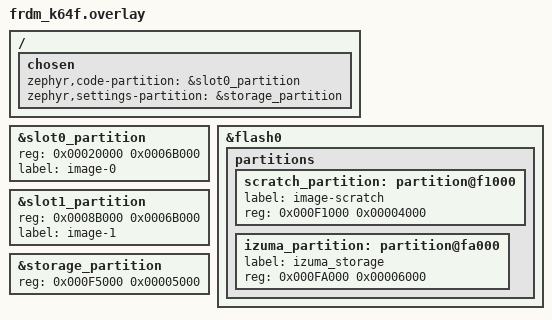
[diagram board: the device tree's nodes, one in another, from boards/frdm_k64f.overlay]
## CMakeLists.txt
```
cmake_minimum_required(VERSION 3.13.1)

# Define configuration files.
set(CONF_FILE "${CMAKE_SOURCE_DIR}/pal-platform/SDK/ZephyrOS/prj.conf")

if (EXISTS "${CMAKE_CURRENT_SOURCE_DIR}/pal-platform/SDK/ZephyrOS/boards/${BOARD}.overlay")
    set(DTC_OVERLAY_FILE "${CMAKE_SOURCE_DIR}/pal-platform/SDK/ZephyrOS/boards/${BOARD}.overlay")
endif()

# Copy Kconfig file to application root for Zephyr to pick it up
configure_file(${CMAKE_SOURCE_DIR}/pal-platform/SDK/ZephyrOS/Kconfig ${CMAKE_SOURCE_DIR} COPYONLY)

find_package(Zephyr REQUIRED HINTS $ENV{ZEPHYR_BASE})
project("Izuma Client")

################################################################################

add_definitions(-DMBED_CONF_APP_DEVELOPER_MODE=$<BOOL:${CONFIG_IZUMA_EXAMPLE_DEVELOPER_MODE}>)

add_definitions(-DMBED_CLOUD_APPLICATION_NONSTANDARD_ENTRYPOINT=1)
add_definitions(-DPAL_USER_DEFINED_CONFIGURATION="pal_config_zephyr.h")
add_definitions(-DPAL_USE_HW_TRNG=1)

# Keep Izuma tracing enabled but limit verbosity to reduce rodata
# and disable certificate enrollment to save flash.
target_compile_definitions(zephyr_interface INTERFACE
    MBED_TRACE_MAX_LEVEL=TRACE_LEVEL_INFO
    MBED_CONF_MBED_CLOUD_CLIENT_DISABLE_CERTIFICATE_ENROLLMENT=1
)

include_directories(${CMAKE_SOURCE_DIR}/pal-platform/SDK/ZephyrOS)
include_directories(${CMAKE_SOURCE_DIR})
include_directories(${CMAKE_SOURCE_DIR}/source)
include_directories(${CMAKE_SOURCE_DIR}/source/include)
include_directories(${CMAKE_SOURCE_DIR}/source/platform/include)

SET(APP_SRCS
    ${CMAKE_SOURCE_DIR}/main.cpp
    ${CMAKE_SOURCE_DIR}/update_ui_example.cpp
    ${CMAKE_SOURCE_DIR}/source/pdmc_example.cpp
    ${CMAKE_SOURCE_DIR}/source/application_init.cpp
    ${CMAKE_SOURCE_DIR}/source/blinky.cpp
    ${CMAKE_SOURCE_DIR}/source/certificate_enrollment_user_cb.cpp
    ${CMAKE_SOURCE_DIR}/source/platform/ZephyrOS/mcc_common_button_and_led.c
    ${CMAKE_SOURCE_DIR}/source/platform/ZephyrOS/mcc_common_setup.c
    ${CMAKE_SOURCE_DIR}/mbed_cloud_dev_credentials.c
    ${CMAKE_SOURCE_DIR}/update_default_resources.c
)

target_sources(app PRIVATE ${CMAKE_SOURCE_DIR}/pal-platform/SDK/ZephyrOS/src/main.cpp ${APP_SRCS})

if(CONFIG_IZUMA_SOURCES)
  target_include_directories(app PRIVATE ${ZEPHYR_BASE}/subsys/storage/flash_map)
  # Copy configuration file to include directory visible for all libraries.
  # Needed for the file to be visible by Zephyr's mbedtls library.
  configure_file("${CMAKE_SOURCE_DIR}/pal-platform/SDK/ZephyrOS/config-tls-generic.h" "${CMAKE_BINARY_DIR}/zephyr/include/generated" COPYONLY)
endif()
```

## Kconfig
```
# Copyright (c) 2021 Pelion
# SPDX-License-Identifier: Apache-2.0

menu "Pelion Device Management Client Example"

comment "    Example application configuration                         "

config PELION_EXAMPLE_DEVELOPER_MODE
    bool "Enable developer mode to skip Factory enrollment"
    default y
    help
      Connect to Pelion DM using developer credentials.

comment "    Library configuration can be found under:                 "
comment "        Modules -> Pelion Device Management Client Library    "

endmenu

source "Kconfig.zephyr"
```

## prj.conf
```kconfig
# Use developer credentials
CONFIG_IZUMA_EXAMPLE_DEVELOPER_MODE=y
CONFIG_IZUMA_UPDATE_DEVELOPER=y

# Enable Pelion Client library
CONFIG_IZUMA_CLIENT=y

# Endpoint type
CONFIG_IZUMA_ENDPOINT_TYPE="default"

# Device registration lifetime
CONFIG_IZUMA_LIFETIME=86400

# Transport mode
CONFIG_IZUMA_TRANSPORT_MODE_TCP=y
#CONFIG_IZUMA_TRANSPORT_MODE_UDP=y
#CONFIG_IZUMA_TRANSPORT_MODE_UDP_QUEUE=y

# CoAP block size
CONFIG_IZUMA_COAP_MAX_BLOCKWISE_PAYLOAD_SIZE=512

# Debug tracing
CONFIG_IZUMA_DEBUG_TRACE=y

# Enable firmware update
CONFIG_IZUMA_UPDATE=y

# Firmware update buffer
CONFIG_IZUMA_UPDATE_BUFFER=1024

# Make new firmware permanent
CONFIG_IZUMA_UPDATE_PERMANENT=y

################################################################################
## Common Zephyr configuration
################################################################################

# Use Mbed TLS from Zephyr with configuration file
CONFIG_MBEDTLS=y
CONFIG_CUSTOM_MBEDTLS_CFG_FILE=y

# Required by Pelion client
CONFIG_NEWLIB_LIBC=y
CONFIG_CPLUSPLUS=y
CONFIG_LIB_CPLUSPLUS=y

# Reduce flash usage: disable float printf and enable LTO
CONFIG_NEWLIB_LIBC_FLOAT_PRINTF=n
# CONFIG_LTO is not available in Zephyr 2.7; leave disabled

# Provide access to flash
CONFIG_FLASH=y
CONFIG_FLASH_MAP=y
CONFIG_FLASH_PAGE_LAYOUT=y
CONFIG_MPU_ALLOW_FLASH_WRITE=y

# Factory provisioning is done in main thread
CONFIG_MAIN_STACK_SIZE=8192

################################################################################
## Network settings
################################################################################

CONFIG_POSIX_API=y

CONFIG_NETWORKING=y
CONFIG_NET_TCP=y
CONFIG_NET_SOCKETS=y
CONFIG_NET_IPV4=y
CONFIG_NET_UDP=y

CONFIG_DNS_RESOLVER=y

CONFIG_NET_DHCPV4=y

CONFIG_NET_MGMT=y
CONFIG_NET_MGMT_EVENT=y
```

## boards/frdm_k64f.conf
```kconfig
# Izuma TDB internal storage configuration
CONFIG_IZUMA_TDB_INTERNAL_STORAGE_SIZE=0x6000
```

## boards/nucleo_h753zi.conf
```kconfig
# --- Console / logging (VCP on USART3) ---
CONFIG_UART_CONSOLE=y
CONFIG_LOG=y
CONFIG_LOG_DEFAULT_LEVEL=3

# --- Stacks/heap (M7 needs more headroom) ---
CONFIG_ISR_STACK_SIZE=4096
CONFIG_HEAP_MEM_POOL_SIZE=32768

# --- Networking driver knobs (if you will use on-board Ethernet) ---
CONFIG_ETH_STM32_HAL=y
CONFIG_NET_L2_ETHERNET=y
CONFIG_NET_IPV4=y
CONFIG_NET_DHCPV4=y

# --- Optional stability knobs (nice during bring-up) ---
CONFIG_ASSERT=y
CONFIG_DEBUG_OPTIMIZATIONS=y

CONFIG_NVS=y

# Izuma TDB internal storage configuration
CONFIG_IZUMA_TDB_INTERNAL_STORAGE_SIZE=0x40000

CONFIG_IZUMA_UPDATE_PAGE_SIZE=32
```

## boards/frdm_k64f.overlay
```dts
/* Align partitions to fit a larger signed image and trailer while staying within 1 MiB
 * Layout summary (addresses in hex):
 *   MCUBoot          : 00000000 - 0001FFFF (128 KiB)
 *   slot0 (image-0)  : 00020000 - 0008AFFF (0x6B000 = 438,272 B)
 *   slot1 (image-1)  : 0008B000 - 000F0FFF (0x6B000)
 *   image-scratch    : 000F1000 - 000F4FFF (0x4000 = 16 KiB)
 *   storage          : 000F5000 - 000FAFFF (0x6000 = 24 KiB)
 *   izuma_storage    : 000FB000 - 000FFFFF (0x5000 = 20 KiB)
 */
/ { chosen { zephyr,code-partition = &slot0_partition; zephyr,settings-partition = &storage_partition; }; };
/delete-node/ &scratch_partition;



/* Common to both MCUboot and APP overlays */
&slot0_partition { reg = <0x00020000 0x0006B000>; label = "image-0"; };
&flash0 {
  partitions {
    scratch_partition: partition@f1000 {   /* 0xF1000–0xF4FFF (16 KiB) */
      label = "image-scratch";
      reg = <0x000F1000 0x00004000>;
    };
  };
};

&slot1_partition { reg = <0x0008B000 0x0006B000>; label = "image-1"; };

&flash0 {
  partitions {
    izuma_partition: partition@fa000 {     /* 0xFA000–0xFFFFF (24 KiB) */
      label = "izuma_storage";
      reg = <0x000FA000 0x00006000>;
    };
    /* We intentionally do not redefine scratch_partition here to avoid duplicating the board-defined label.
     * The board DTS defines scratch_partition with label "image-scratch"; we keep it but shrink it via a
     * delete+recreate below with the same label and a new address range.
     */
  };
};

/* Reposition existing settings/storage partition provided by the board DTS */
&storage_partition {
  reg = <0x000F5000 0x00005000>;
};
```

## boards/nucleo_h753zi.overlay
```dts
/* App executes from slot0; Settings use 'storage' */
&{/chosen} {
	zephyr,code-partition = &slot0_partition;
	zephyr,settings-partition = &storage_partition;
};

/* Storage/NVS: 256 KiB (2 x 128 KiB) */
&storage_partition {
	reg = <0x00020000 0x00040000>;
	label = "storage";
};

/* Slots: 640 KiB each */
&slot0_partition {
	reg = <0x00060000 0x000A0000>;
	label = "image-0";
};

&slot1_partition {
	reg = <0x00100000 0x000A0000>;
	label = "image-1";
};

/* Izuma creds: 256 KiB (2 x 128 KiB) */
&flash0 {
	partitions {
		izuma_partition: partition@100000 {
			label = "izuma_storage";
			reg = <0x001A0000 0x00040000>;
		};
	};
};

/* Scratch: 128 KiB at end of flash */
&scratch_partition {
	reg = <0x001E0000 0x00020000>;
	label = "image-scratch";
};
```

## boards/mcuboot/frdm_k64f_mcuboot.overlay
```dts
&{/chosen} { zephyr,code-partition = &boot_partition; };

/* Common to both MCUboot and APP overlays */
&slot0_partition { reg = <0x00020000 0x00065000>; label = "image-0"; };
&slot1_partition { reg = <0x00085000 0x00065000>; label = "image-1"; };

&flash0 {
  partitions {
    storage_partition: partition@e1000 {  /* 0xE1000–0xE9FFF (36 KiB) */
      label = "storage";
      reg = <0x000E1000 0x00009000>;
    };
    scratch_partition: partition@ea000 {   /* 0xEA000–0xF9FFF (64 KiB) */
      label = "image-scratch";
      reg = <0x000EA000 0x00010000>;
    };
    izuma_partition: partition@fa000 {     /* 0xFA000–0xFFFFF (24 KiB) */
      label = "izuma_storage";
      reg = <0x000FA000 0x00006000>;
    };
  };
};
```

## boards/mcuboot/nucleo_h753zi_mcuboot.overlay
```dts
/* Bootloader runs from the boot partition */
&{/chosen} {
	zephyr,code-partition = &boot_partition;
};

/* Storage/NVS: 256 KiB (2 x 128 KiB) */
&storage_partition {
	reg = <0x00020000 0x00040000>;
	label = "storage";
};

/* Slots: 640 KiB each */
&slot0_partition {
	reg = <0x00060000 0x000A0000>;
	label = "image-0";
};

&slot1_partition {
	reg = <0x00100000 0x000A0000>;
	label = "image-1";
};

/* Izuma creds: 256 KiB (2 x 128 KiB) */
&flash0 {
	partitions {
		izuma_partition: partition@100000 {
			label = "izuma_storage";
			reg = <0x001A0000 0x00040000>;
		};
	};
};

/* Scratch: 128 KiB at end of flash */
&scratch_partition {
	reg = <0x001E0000 0x00020000>;
	label = "image-scratch";
};
```

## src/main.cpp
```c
/* Copyright (c) 2021 Pelion
 * Copyright (c) 2023 Izuma Networks
 *
 * Licensed under the Apache License, Version 2.0 (the "License");
 * you may not use this file except in compliance with the License.
 * You may obtain a copy of the License at
 *
 *     http://www.apache.org/licenses/LICENSE-2.0
 *
 * Unless required by applicable law or agreed to in writing, software
 * distributed under the License is distributed on an "AS IS" BASIS,
 * WITHOUT WARRANTIES OR CONDITIONS OF ANY KIND, either express or implied.
 * See the License for the specific language governing permissions and
 * limitations under the License.
 */

#include <zephyr/zephyr.h>
#include <zephyr/net/net_if.h>
#include <zephyr/net/dhcpv4.h>
#include <zephyr/net/net_mgmt.h>

#include <stdio.h>

extern "C" int mbed_cloud_application_entrypoint(void);

int main(void)
{
	printf("Izuma Device Management Client Example - 2.0.0\r\n");

    struct net_if *iface = net_if_get_default();

    net_dhcpv4_start(iface);

    net_mgmt_event_wait(NET_EVENT_IPV4_ADDR_ADD, NULL, NULL, NULL, NULL, K_FOREVER);

	mbed_cloud_application_entrypoint();
	
	return 0;
}
```
